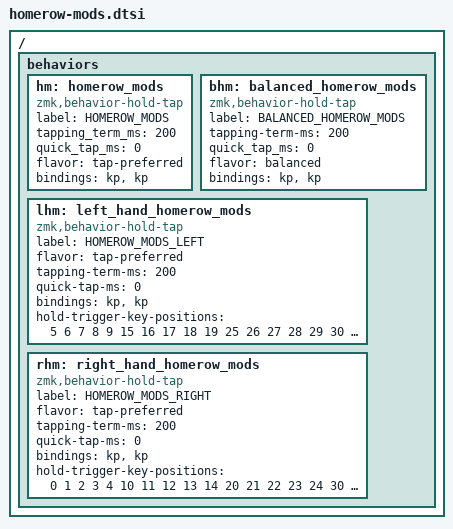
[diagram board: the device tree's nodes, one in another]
/ {
	behaviors {
		hm: homerow_mods {
			compatible = "zmk,behavior-hold-tap";
			label = "HOMEROW_MODS";
			#binding-cells = <2>;
			tapping_term_ms = <200>;
			quick_tap_ms = <0>;
			flavor = "tap-preferred";
			bindings = <&kp>, <&kp>;
		};

		bhm: balanced_homerow_mods {
			compatible = "zmk,behavior-hold-tap";
			label = "BALANCED_HOMEROW_MODS";
			#binding-cells = <2>;
			tapping-term-ms = <200>;
			quick_tap_ms = <0>;
			flavor = "balanced";
			bindings = <&kp>, <&kp>;
		};

		lhm: left_hand_homerow_mods {
            compatible = "zmk,behavior-hold-tap";
            label = "HOMEROW_MODS_LEFT";
            #binding-cells = <2>;
            flavor = "tap-preferred";
            tapping-term-ms = <200>;
            quick-tap-ms = <0>;
            bindings = <&kp>, <&kp>;
            hold-trigger-key-positions = <
				5  6  7  8  9 
				15 16 17 18 19 
				25 26 27 28 29 
	   30 31 32 33 34 35
			>;
        };

		rhm: right_hand_homerow_mods {
            compatible = "zmk,behavior-hold-tap";
            label = "HOMEROW_MODS_RIGHT";
            #binding-cells = <2>;
            flavor = "tap-preferred";
            tapping-term-ms = <200>;
            quick-tap-ms = <0>;
            bindings = <&kp>, <&kp>;
            hold-trigger-key-positions = <
				0  1  2  3  4 
				10 11 12 13 14 
				20 21 22 23 24 
					  30 31 32 33 34 35
			>;
        };
	};
};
